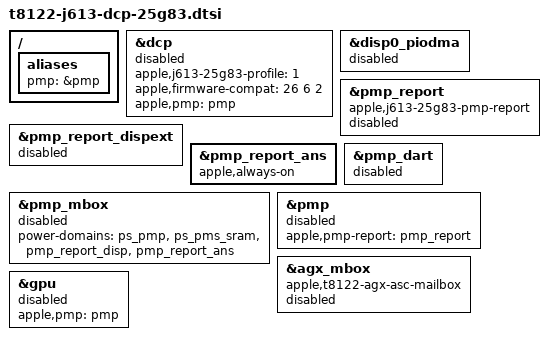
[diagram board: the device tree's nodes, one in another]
// SPDX-License-Identifier: GPL-2.0+ OR MIT
/* J613 25G83: inherit the hardware wiring, select a separate firmware ABI.
 * No board tunables or DMA mappings are embedded. The boot loader passes
 * this Mac's PMP values and validates the running display's mappings.
 */
/ {
	aliases {
		pmp = &pmp;
	};
};

&dcp {
	apple,j613-25g83-profile = <1>;
	apple,firmware-compat = <26 6 2>;
	apple,pmp = <&pmp>;
	/delete-property/ clocks;
	status = "disabled";
};

&disp0_piodma {
	status = "disabled";
};

/* Reuse the complete Asahi PMP topology, with this profile left disabled. */
&pmp_report {
	compatible = "apple,j613-25g83-pmp-report";
	status = "disabled";
};

/* This profile requests only DISP and ANS until external admission succeeds. */
&pmp_report_dispext {
	status = "disabled";
};

&pmp_report_ans {
	apple,always-on;
};

&pmp_dart {
	status = "disabled";
};

&pmp_mbox {
	power-domains = <&ps_pmp>, <&ps_pms_sram>,
			<&pmp_report_disp>, <&pmp_report_ans>;
	status = "disabled";
};

&pmp {
	apple,pmp-report = <&pmp_report>;
	status = "disabled";
};

/* The 25G83 GPU uses the native ASC mailbox and the same PMP supplier.
 * Firmware mappings and calibration are supplied by the boot loader.
 */
&agx_mbox {
	compatible = "apple,t8122-agx-asc-mailbox", "apple,asc-mailbox-v4";
	status = "disabled";
};

&gpu {
	apple,pmp = <&pmp>;
	status = "disabled";
};
